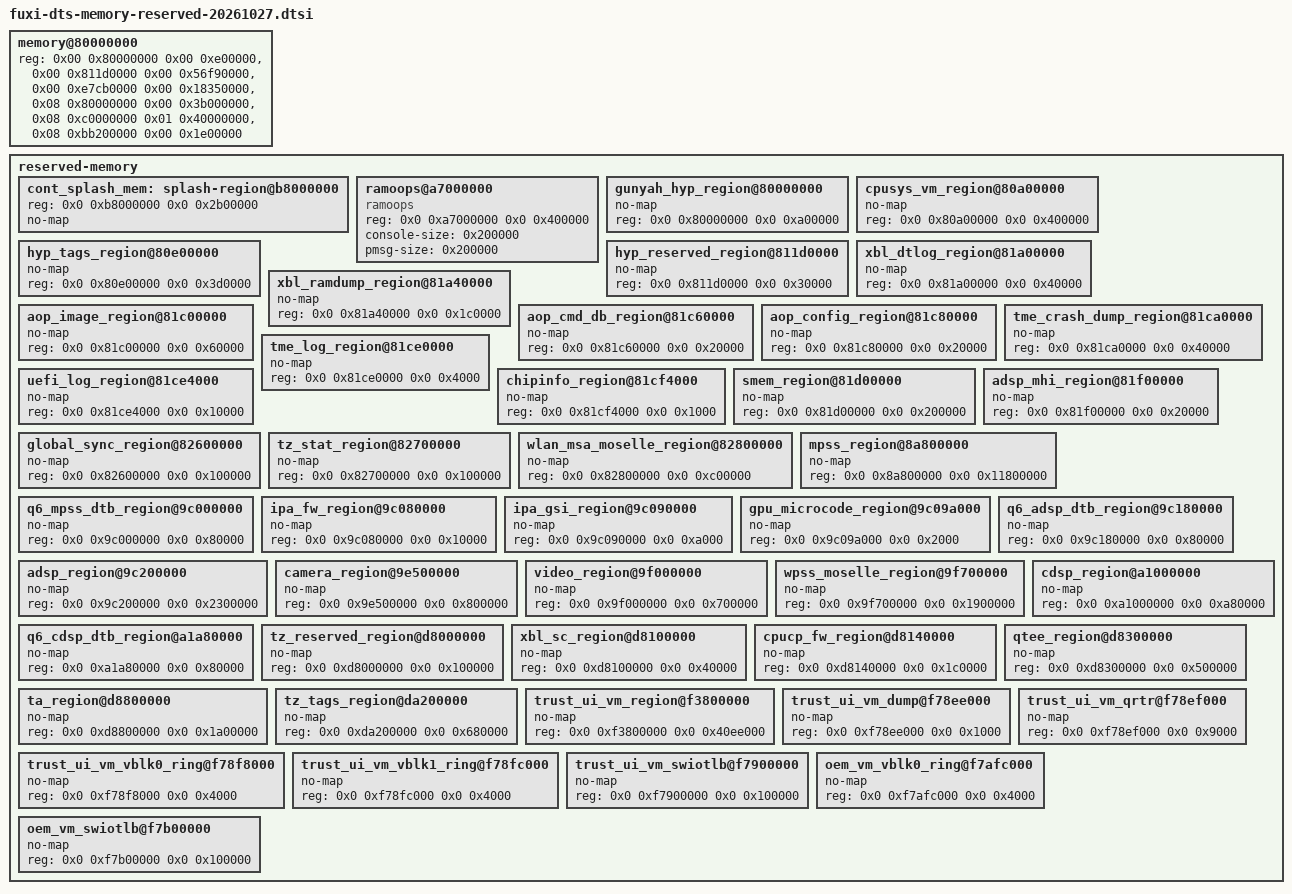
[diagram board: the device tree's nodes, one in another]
	/* 内存布局取自厂商 fuxi.dtb 的 /memory 节点（去掉零长度项） */
	memory@80000000 {
		device_type = "memory";
		reg = <0x00 0x80000000 0x00 0xe00000>,
		      <0x00 0x811d0000 0x00 0x56f90000>,
		      <0x00 0xe7cb0000 0x00 0x18350000>,
		      <0x08 0x80000000 0x00 0x3b000000>,
		      <0x08 0xc0000000 0x01 0x40000000>,
		      <0x08 0xbb200000 0x00 0x1e00000>;
	};
	reserved-memory {
		#address-cells = <2>;
		#size-cells = <2>;
		ranges;

		/* 厂商 DTB 的 cont_splash_region：bootloader 帧缓冲，不能给内核当普通内存用 */
		cont_splash_mem: splash-region@b8000000 {
			reg = <0x0 0xb8000000 0x0 0x2b00000>;
			no-map;
		};

		/*
		 * 与 Android vendor DTB 完全一致的 pstore/ramoops 区域。
		 * 主线内核把 printk 写进这里；复位后 Android 的 pstore 驱动
		 * 会在 /sys/fs/pstore 下暴露 console-ramoops-0，可 adb 读取。
		 */
		ramoops@a7000000 {
			compatible = "ramoops";
			reg = <0x0 0xa7000000 0x0 0x400000>;
			console-size = <0x200000>;
			pmsg-size = <0x200000>;
		};

		gunyah_hyp_region@80000000 {
			no-map;
			reg = <0x0 0x80000000 0x0 0xa00000>;
		};
		cpusys_vm_region@80a00000 {
			no-map;
			reg = <0x0 0x80a00000 0x0 0x400000>;
		};
		hyp_tags_region@80e00000 {
			no-map;
			reg = <0x0 0x80e00000 0x0 0x3d0000>;
		};
		hyp_reserved_region@811d0000 {
			no-map;
			reg = <0x0 0x811d0000 0x0 0x30000>;
		};
		xbl_dtlog_region@81a00000 {
			no-map;
			reg = <0x0 0x81a00000 0x0 0x40000>;
		};
		xbl_ramdump_region@81a40000 {
			no-map;
			reg = <0x0 0x81a40000 0x0 0x1c0000>;
		};
		aop_image_region@81c00000 {
			no-map;
			reg = <0x0 0x81c00000 0x0 0x60000>;
		};
		aop_cmd_db_region@81c60000 {
			no-map;
			reg = <0x0 0x81c60000 0x0 0x20000>;
		};
		aop_config_region@81c80000 {
			no-map;
			reg = <0x0 0x81c80000 0x0 0x20000>;
		};
		tme_crash_dump_region@81ca0000 {
			no-map;
			reg = <0x0 0x81ca0000 0x0 0x40000>;
		};
		tme_log_region@81ce0000 {
			no-map;
			reg = <0x0 0x81ce0000 0x0 0x4000>;
		};
		uefi_log_region@81ce4000 {
			no-map;
			reg = <0x0 0x81ce4000 0x0 0x10000>;
		};
		chipinfo_region@81cf4000 {
			no-map;
			reg = <0x0 0x81cf4000 0x0 0x1000>;
		};
		smem_region@81d00000 {
			no-map;
			reg = <0x0 0x81d00000 0x0 0x200000>;
		};
		adsp_mhi_region@81f00000 {
			no-map;
			reg = <0x0 0x81f00000 0x0 0x20000>;
		};
		global_sync_region@82600000 {
			no-map;
			reg = <0x0 0x82600000 0x0 0x100000>;
		};
		tz_stat_region@82700000 {
			no-map;
			reg = <0x0 0x82700000 0x0 0x100000>;
		};
		wlan_msa_moselle_region@82800000 {
			no-map;
			reg = <0x0 0x82800000 0x0 0xc00000>;
		};
		mpss_region@8a800000 {
			no-map;
			reg = <0x0 0x8a800000 0x0 0x11800000>;
		};
		q6_mpss_dtb_region@9c000000 {
			no-map;
			reg = <0x0 0x9c000000 0x0 0x80000>;
		};
		ipa_fw_region@9c080000 {
			no-map;
			reg = <0x0 0x9c080000 0x0 0x10000>;
		};
		ipa_gsi_region@9c090000 {
			no-map;
			reg = <0x0 0x9c090000 0x0 0xa000>;
		};
		gpu_microcode_region@9c09a000 {
			no-map;
			reg = <0x0 0x9c09a000 0x0 0x2000>;
		};
		q6_adsp_dtb_region@9c180000 {
			no-map;
			reg = <0x0 0x9c180000 0x0 0x80000>;
		};
		adsp_region@9c200000 {
			no-map;
			reg = <0x0 0x9c200000 0x0 0x2300000>;
		};
		camera_region@9e500000 {
			no-map;
			reg = <0x0 0x9e500000 0x0 0x800000>;
		};
		video_region@9f000000 {
			no-map;
			reg = <0x0 0x9f000000 0x0 0x700000>;
		};
		wpss_moselle_region@9f700000 {
			no-map;
			reg = <0x0 0x9f700000 0x0 0x1900000>;
		};
		cdsp_region@a1000000 {
			no-map;
			reg = <0x0 0xa1000000 0x0 0xa80000>;
		};
		q6_cdsp_dtb_region@a1a80000 {
			no-map;
			reg = <0x0 0xa1a80000 0x0 0x80000>;
		};
		tz_reserved_region@d8000000 {
			no-map;
			reg = <0x0 0xd8000000 0x0 0x100000>;
		};
		xbl_sc_region@d8100000 {
			no-map;
			reg = <0x0 0xd8100000 0x0 0x40000>;
		};
		cpucp_fw_region@d8140000 {
			no-map;
			reg = <0x0 0xd8140000 0x0 0x1c0000>;
		};
		qtee_region@d8300000 {
			no-map;
			reg = <0x0 0xd8300000 0x0 0x500000>;
		};
		ta_region@d8800000 {
			no-map;
			reg = <0x0 0xd8800000 0x0 0x1a00000>;
		};
		tz_tags_region@da200000 {
			no-map;
			reg = <0x0 0xda200000 0x0 0x680000>;
		};
		trust_ui_vm_region@f3800000 {
			no-map;
			reg = <0x0 0xf3800000 0x0 0x40ee000>;
		};
		trust_ui_vm_dump@f78ee000 {
			no-map;
			reg = <0x0 0xf78ee000 0x0 0x1000>;
		};
		trust_ui_vm_qrtr@f78ef000 {
			no-map;
			reg = <0x0 0xf78ef000 0x0 0x9000>;
		};
		trust_ui_vm_vblk0_ring@f78f8000 {
			no-map;
			reg = <0x0 0xf78f8000 0x0 0x4000>;
		};
		trust_ui_vm_vblk1_ring@f78fc000 {
			no-map;
			reg = <0x0 0xf78fc000 0x0 0x4000>;
		};
		trust_ui_vm_swiotlb@f7900000 {
			no-map;
			reg = <0x0 0xf7900000 0x0 0x100000>;
		};
		oem_vm_vblk0_ring@f7afc000 {
			no-map;
			reg = <0x0 0xf7afc000 0x0 0x4000>;
		};
		oem_vm_swiotlb@f7b00000 {
			no-map;
			reg = <0x0 0xf7b00000 0x0 0x100000>;
		};
	};

